VERSION ""

NS_ :

BS_:

BU_: XXX

BO_ 85 CID_MCWFAP: 8 XXX
 SG_ sig_uioige : 40|1@1+ (1,0) [0|1] "" XXX
 SG_ sig_wxbhky : 56|8@1+ (1,0) [0|255] "" XXX

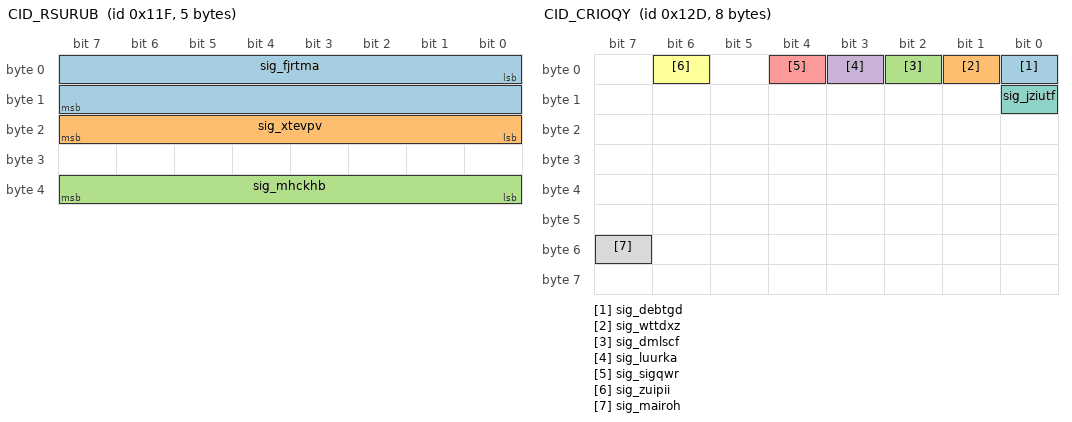
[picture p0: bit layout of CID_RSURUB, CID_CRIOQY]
BO_ 287 CID_RSURUB: 5 XXX
 SG_ sig_fjrtma : 0|16@1- (0.1,0) [-450|450] "" XXX
 SG_ sig_xtevpv : 16|8@1+ (4,0) [0|1020] "" XXX
 SG_ sig_mhckhb : 32|8@1+ (1,0) [0|255] "" XXX

BO_ 289 CID_NVMJEF: 8 XXX
 SG_ sig_wjivje : 0|12@1+ (1,0) [0|255] "" XXX

BO_ 301 CID_CRIOQY: 8 XXX
 SG_ sig_debtgd : 0|1@0+ (1,0) [0|1] "" XXX
 SG_ sig_wttdxz : 1|1@0+ (1,0) [0|1] "" XXX
 SG_ sig_dmlscf : 2|1@0+ (1,0) [0|1] "" XXX
 SG_ sig_luurka : 3|1@0+ (1,0) [0|1] "" XXX
 SG_ sig_sigqwr : 4|1@0+ (1,0) [0|1] "" XXX
 SG_ sig_zuipii : 6|1@0+ (1,0) [0|1] "" XXX
 SG_ sig_jziutf : 8|1@0+ (1,0) [0|1] "" XXX
 SG_ sig_mairoh : 55|1@0+ (1,0) [0|1] "" XXX

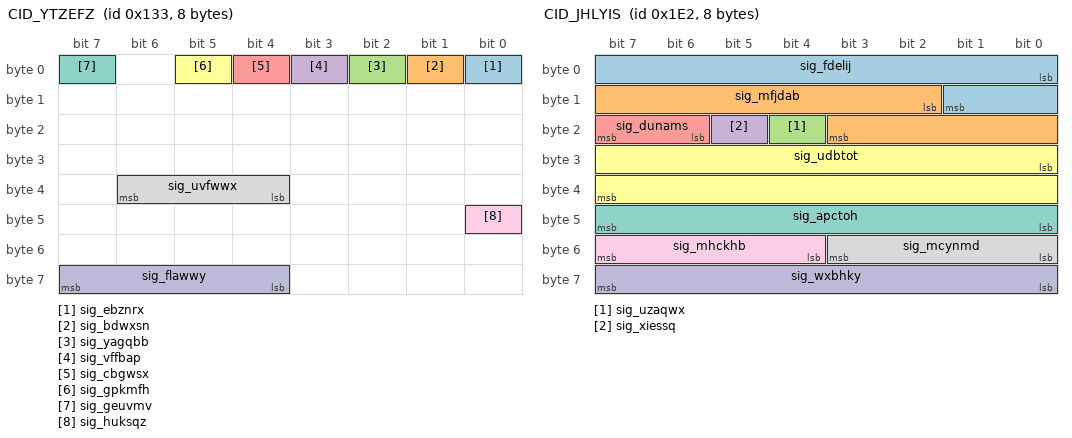
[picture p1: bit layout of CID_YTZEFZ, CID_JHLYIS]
BO_ 307 CID_YTZEFZ: 8 XXX
 SG_ sig_ebznrx : 0|1@0+ (1,0) [0|1] "" XXX
 SG_ sig_bdwxsn : 1|1@1+ (1,0) [0|1] "" XXX
 SG_ sig_yagqbb : 2|1@1+ (1,0) [0|1] "" XXX
 SG_ sig_vffbap : 3|1@1+ (1,0) [0|1] "" XXX
 SG_ sig_cbgwsx : 4|1@0+ (1,0) [0|1] "" XXX
 SG_ sig_gpkmfh : 5|1@0+ (1,0) [0|1] "" XXX
 SG_ sig_geuvmv : 7|1@0+ (1,0) [0|1] "" XXX
 SG_ sig_uvfwwx : 36|3@1+ (1,0) [0|7] "" XXX
 SG_ sig_huksqz : 40|1@0+ (1,0) [0|1] "" XXX
 SG_ sig_flawwy : 63|4@0+ (1,0) [0|15] "" XXX

BO_ 482 CID_JHLYIS: 8 XXX
 SG_ sig_fdelij : 0|10@1- (0.01,0) [0|5] "" XXX
 SG_ sig_mfjdab : 10|10@1- (0.01,0) [-5|0] "" XXX
 SG_ sig_uzaqwx : 20|1@0+ (1,0) [0|1] "" XXX
 SG_ sig_xiessq : 21|1@0+ (1,0) [0|1] "" XXX
 SG_ sig_dunams : 22|2@1+ (1,0) [0|1] "" XXX
 SG_ sig_udbtot : 24|16@1- (0.1,0) [-780|779.9] "" XXX
 SG_ sig_apctoh : 47|8@0+ (1,0) [0|255] "" XXX
 SG_ sig_mcynmd : 48|4@1+ (1,0) [0|15] "" XXX
 SG_ sig_mhckhb : 52|4@1+ (1,0) [0|15] "" XXX
 SG_ sig_wxbhky : 56|8@1+ (1,0) [0|255] "" XXX

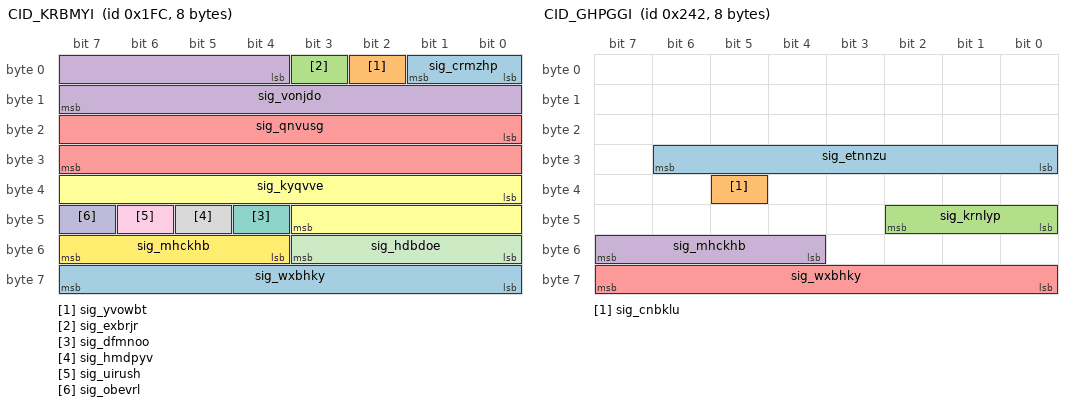
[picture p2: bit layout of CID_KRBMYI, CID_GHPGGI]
BO_ 508 CID_KRBMYI: 8 XXX
 SG_ sig_crmzhp : 0|2@1+ (1,0) [0|1] "" XXX
 SG_ sig_yvowbt : 2|1@1+ (1,0) [0|1] "" XXX
 SG_ sig_exbrjr : 3|1@0+ (1,0) [0|1] "" XXX
 SG_ sig_vonjdo : 4|12@1- (1,0) [-2048|2047] "" XXX
 SG_ sig_qnvusg : 16|16@1- (0.1,0) [-780|779.9] "Deg" XXX
 SG_ sig_kyqvve : 32|12@1- (0.01,0) [0|63] "" XXX
 SG_ sig_dfmnoo : 44|1@0+ (1,0) [0|1] "" XXX
 SG_ sig_hmdpyv : 45|1@1+ (1,0) [0|255] "" XXX
 SG_ sig_uirush : 46|1@1+ (1,0) [0|1] "" XXX
 SG_ sig_obevrl : 47|1@0+ (1,0) [0|3] "" XXX
 SG_ sig_hdbdoe : 48|4@1+ (1,0) [0|15] "" XXX
 SG_ sig_mhckhb : 52|4@1+ (1,0) [0|15] "" XXX
 SG_ sig_wxbhky : 56|8@1+ (1,0) [0|255] "" XXX

BO_ 578 CID_GHPGGI: 8 XXX
 SG_ sig_etnnzu : 30|7@0+ (1,0) [0|127] "" XXX
 SG_ sig_cnbklu : 37|1@0+ (1,0) [0|1] "" XXX
 SG_ sig_krnlyp : 40|3@1+ (1,0) [0|7] "" XXX
 SG_ sig_mhckhb : 55|4@0+ (1,0) [0|15] "" XXX
 SG_ sig_wxbhky : 56|8@1+ (1,0) [0|255] "" XXX

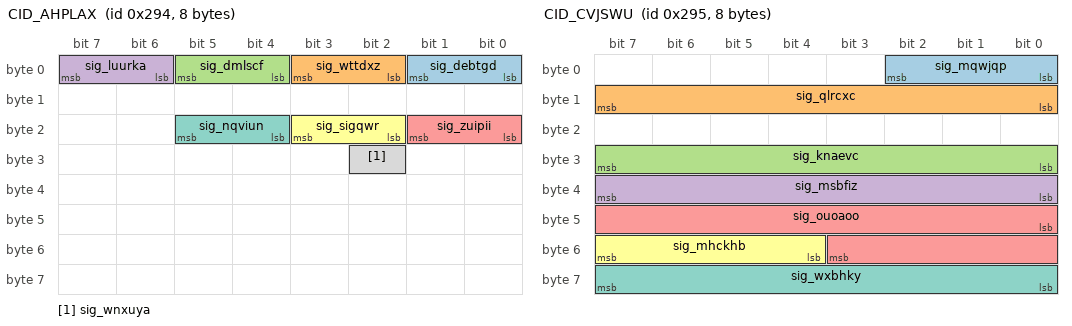
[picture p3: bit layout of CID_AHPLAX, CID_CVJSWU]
BO_ 660 CID_AHPLAX: 8 XXX
 SG_ sig_debtgd : 1|2@0+ (1,0) [0|3] "" XXX
 SG_ sig_wttdxz : 3|2@0+ (1,0) [0|3] "" XXX
 SG_ sig_dmlscf : 5|2@0+ (1,0) [0|3] "" XXX
 SG_ sig_luurka : 7|2@0+ (1,0) [0|3] "" XXX
 SG_ sig_zuipii : 17|2@0+ (1,0) [0|3] "" XXX
 SG_ sig_sigqwr : 19|2@0+ (1,0) [0|3] "" XXX
 SG_ sig_nqviun : 21|2@0+ (1,0) [0|3] "" XXX
 SG_ sig_wnxuya : 26|1@0+ (1,0) [0|1] "" XXX

BO_ 661 CID_CVJSWU: 8 XXX
 SG_ sig_mqwjqp : 2|3@0+ (1,0) [0|7] "" XXX
 SG_ sig_qlrcxc : 15|8@0+ (1,0) [0|255] "" XXX
 SG_ sig_knaevc : 31|8@0+ (1,0) [0|255] "" XXX
 SG_ sig_msbfiz : 32|8@1+ (1,0) [0|255] "" XXX
 SG_ sig_ouoaoo : 40|12@1+ (1,0) [0|255] "" XXX
 SG_ sig_mhckhb : 52|4@1+ (1,0) [0|15] "" XXX
 SG_ sig_wxbhky : 63|8@0+ (1,0) [0|255] "" XXX

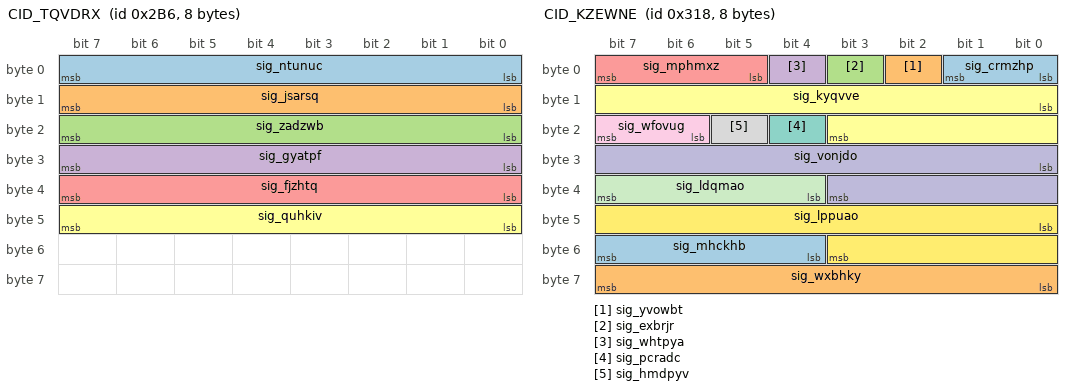
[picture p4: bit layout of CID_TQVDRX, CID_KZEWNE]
BO_ 694 CID_TQVDRX: 8 XXX
 SG_ sig_ntunuc : 7|8@0+ (1,0) [0|255] "" XXX
 SG_ sig_jsarsq : 15|8@0+ (1,0) [0|255] "" XXX
 SG_ sig_zadzwb : 23|8@0+ (1,0) [0|255] "" XXX
 SG_ sig_gyatpf : 31|8@0+ (1,0) [0|255] "" XXX
 SG_ sig_fjzhtq : 39|8@0+ (1,0) [0|255] "" XXX
 SG_ sig_quhkiv : 47|8@0+ (1,0) [0|255] "" XXX

BO_ 790 CID_GXPQAT: 8 XXX
 SG_ sig_eruibt : 3|4@0+ (1,0) [0|1] "" XXX
 SG_ sig_wxtitr : 4|2@1+ (1,0) [0|3] "" XXX
 SG_ sig_ldgngq : 6|2@1+ (1,0) [0|3] "" XXX
 SG_ sig_dbmyfr : 8|2@1+ (1,0) [0|3] "" XXX
 SG_ sig_kfomuy : 10|1@1+ (1,0) [0|1] "" XXX
 SG_ sig_quxrcd : 11|4@1+ (1,0) [0|1] "" XXX
 SG_ sig_xzjvxd : 15|1@0+ (1,0) [0|1] "" XXX
 SG_ sig_udbtot : 16|11@1- (1,0) [-1024|1023] "" XXX
 SG_ sig_uzaqwx : 27|1@1+ (1,0) [0|1] "" XXX
 SG_ sig_xiessq : 28|1@1+ (1,0) [0|3] "" XXX
 SG_ sig_ajmccf : 29|1@0+ (1,0) [0|1] "" XXX
 SG_ sig_bmieza : 30|1@0+ (1,0) [0|1] "" XXX
 SG_ sig_iwgpdw : 31|1@0+ (1,0) [0|1] "" XXX
 SG_ sig_npchrh : 32|2@1+ (1,0) [0|3] "" XXX
 SG_ sig_fcuins : 34|2@1+ (1,0) [0|3] "" XXX
 SG_ sig_bokbfa : 36|4@1+ (1,0) [0|3] "" XXX
 SG_ sig_xgamab : 40|8@1+ (5,-5) [-5|1270] "" XXX
 SG_ sig_jpladc : 49|2@0+ (1,0) [0|3] "" XXX
 SG_ sig_pifmxh : 51|2@0+ (1,0) [0|3] "" XXX
 SG_ sig_mhckhb : 52|4@1+ (1,0) [0|15] "" XXX
 SG_ sig_wxbhky : 56|8@1+ (1,0) [0|15] "" XXX

BO_ 792 CID_KZEWNE: 8 XXX
 SG_ sig_crmzhp : 0|2@1+ (1,0) [0|1] "" XXX
 SG_ sig_yvowbt : 2|1@1+ (1,0) [0|1] "" XXX
 SG_ sig_exbrjr : 3|1@1+ (1,0) [0|1] "" XXX
 SG_ sig_whtpya : 4|1@1+ (1,0) [0|1] "" XXX
 SG_ sig_mphmxz : 5|3@1+ (1,0) [0|1] "" XXX
 SG_ sig_kyqvve : 8|12@1- (1,0) [-2048|2047] "" XXX
 SG_ sig_pcradc : 20|1@1+ (1,0) [0|1] "" XXX
 SG_ sig_hmdpyv : 21|1@1+ (1,0) [0|1] "" XXX
 SG_ sig_wfovug : 22|2@1+ (1,0) [0|15] "" XXX
 SG_ sig_vonjdo : 24|12@1- (1,0) [-2048|2047] "" XXX
 SG_ sig_ldqmao : 36|4@1+ (1,0) [0|15] "" XXX
 SG_ sig_lppuao : 40|12@1+ (1,0) [0|4095] "" XXX
 SG_ sig_mhckhb : 52|4@1+ (1,0) [0|15] "" XXX
 SG_ sig_wxbhky : 56|8@1+ (1,0) [0|255] "" XXX

BO_ 813 CID_YPLUTP: 8 XXX
 SG_ sig_vwattl : 0|9@1+ (0.5,0) [0|255.5] "" XXX
 SG_ sig_aduxzo : 9|1@1+ (1,0) [0|1] "" XXX
 SG_ sig_vftgch : 10|3@1+ (1,0) [0|7] "" XXX
 SG_ sig_vqlcld : 13|3@1+ (1,0) [0|7] "" XXX
 SG_ sig_mdggcb : 16|1@1+ (1,0) [0|1] "" XXX
 SG_ sig_mbklmy : 17|1@1+ (1,0) [0|1] "" XXX
 SG_ sig_exbrjr : 18|1@1+ (1,0) [0|1] "" XXX
 SG_ sig_wngyio : 19|3@1+ (1,0) [0|1] "" XXX
 SG_ sig_pvngdg : 22|1@0+ (1,0) [0|1] "" XXX
 SG_ sig_luquuv : 23|1@0+ (1,0) [0|1] "" XXX
 SG_ sig_dbmyfr : 24|1@1+ (1,0) [0|1] "" XXX
 SG_ sig_blidrr : 25|7@1+ (1,0) [0|127] "" XXX
 SG_ sig_skcftn : 32|4@1+ (1,0) [0|15] "" XXX
 SG_ sig_temxkw : 36|12@1+ (1,0) [0|4095] "" XXX
 SG_ sig_mhckhb : 48|4@1+ (1,0) [0|15] "" XXX
 SG_ sig_rupdao : 55|4@0+ (1,0) [0|15] "" XXX
 SG_ sig_wxbhky : 56|8@1+ (1,0) [0|255] "" XXX

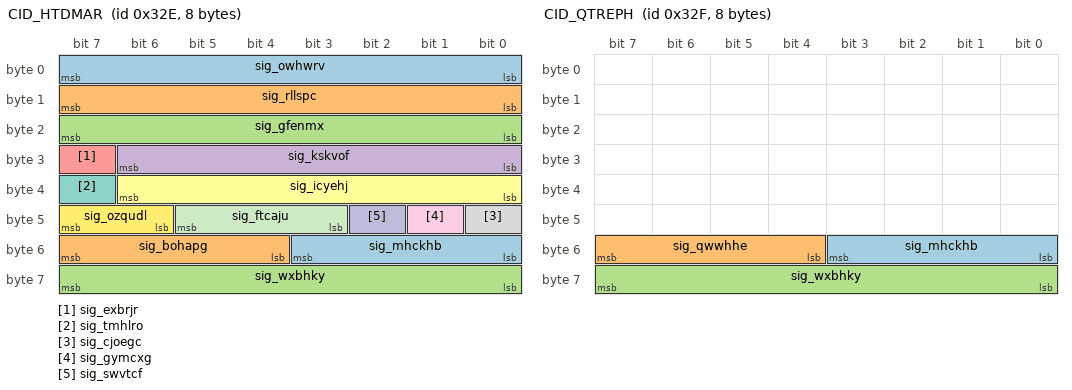
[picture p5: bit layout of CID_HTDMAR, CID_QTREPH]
BO_ 814 CID_HTDMAR: 8 XXX
 SG_ sig_owhwrv : 0|8@1+ (0.05,-5) [-100|155] "" XXX
 SG_ sig_rllspc : 8|8@1+ (0.05,-5) [0|1.26] "" XXX
 SG_ sig_gfenmx : 16|8@1+ (0.05,-5) [0|1.26] "" XXX
 SG_ sig_kskvof : 24|7@1+ (0.2,0) [0|12.7] "" XXX
 SG_ sig_exbrjr : 31|1@0+ (1,0) [0|1] "" XXX
 SG_ sig_icyehj : 32|7@1+ (0.2,-16) [0|12.7] "" XXX
 SG_ sig_tmhlro : 39|1@0+ (1,0) [0|1] "" XXX
 SG_ sig_cjoegc : 40|1@0+ (1,0) [0|1] "" XXX
 SG_ sig_gymcxg : 41|1@0+ (1,0) [0|1] "" XXX
 SG_ sig_swvtcf : 42|1@1+ (1,0) [0|3] "" XXX
 SG_ sig_ftcaju : 45|3@0+ (1,0) [0|1] "" XXX
 SG_ sig_ozqudl : 46|2@1+ (1,0) [0|3] "" XXX
 SG_ sig_mhckhb : 48|4@1+ (1,0) [0|15] "" XXX
 SG_ sig_bohapg : 55|4@0+ (1,0) [0|15] "" XXX
 SG_ sig_wxbhky : 56|8@1+ (1,0) [0|255] "" XXX

BO_ 815 CID_QTREPH: 8 XXX
 SG_ sig_mhckhb : 48|4@1+ (1,0) [0|15] "" XXX
 SG_ sig_qwwhhe : 55|4@0+ (1,0) [0|15] "" XXX
 SG_ sig_wxbhky : 56|8@1+ (1,0) [0|255] "" XXX

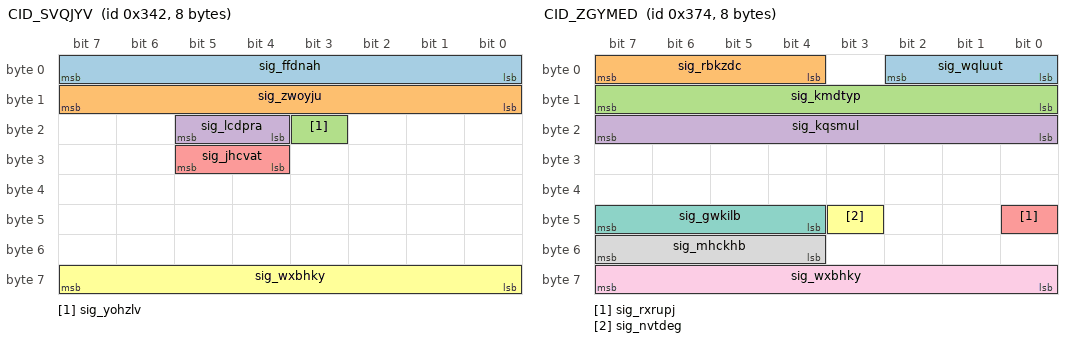
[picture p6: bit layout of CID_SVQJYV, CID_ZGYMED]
BO_ 834 CID_SVQJYV: 8 XXX
 SG_ sig_ffdnah : 0|8@1+ (0.01,0) [0|2.55] "" XXX
 SG_ sig_zwoyju : 8|8@1+ (0.01,0) [0|2.55] "" XXX
 SG_ sig_yohzlv : 19|1@1+ (1,0) [0|1] "" XXX
 SG_ sig_lcdpra : 20|2@1+ (1,0) [0|255] "" XXX
 SG_ sig_jhcvat : 28|2@1+ (1,0) [0|1] "" XXX
 SG_ sig_wxbhky : 56|8@1+ (1,0) [0|255] "" XXX

 BO_ 884 CID_ZGYMED: 8 MRR
 SG_ sig_wqluut : 2|3@0+ (1,0) [0|3] "" MRR
 SG_ sig_rbkzdc : 7|4@0+ (1,0) [0|15] "" MRR
 SG_ sig_kmdtyp : 15|8@0+ (0.1,-12) [0|255] "" MRR
 SG_ sig_kqsmul : 23|8@0+ (1,-100) [0|255] "" MRR
 SG_ sig_rxrupj : 40|1@0+ (1,0) [0|3] "" MRR
 SG_ sig_nvtdeg : 43|1@0+ (1,0) [0|1] "" XXX
 SG_ sig_gwkilb : 44|4@1+ (1,0) [0|15] "" XXX
 SG_ sig_mhckhb : 52|4@1+ (1,0) [0|15] "" MRR
 SG_ sig_wxbhky : 56|8@1+ (1,0) [0|255] "" MRR

BO_ 944 CID_WLXZOF: 8 XXX
 SG_ sig_ezdbxm : 1|2@0+ (1,0) [0|3] "" XXX
 SG_ sig_itykpr : 2|1@0+ (1,0) [0|1] "" XXX
 SG_ sig_tksxga : 4|2@0+ (1,0) [0|3] "" XXX
 SG_ sig_dqfgmo : 5|1@0+ (1,0) [0|1] "" XXX
 SG_ sig_qjgeiy : 6|1@0+ (1,0) [0|1] "" XXX
 SG_ sig_gwhdhq : 7|1@0+ (1,0) [0|1] "" XXX
 SG_ sig_giraji : 8|1@0+ (1,0) [0|1] "" XXX
 SG_ sig_xcvbhu : 11|3@0+ (1,0) [0|7] "" XXX
 SG_ sig_dgobck : 12|1@0+ (1,0) [0|1] "" XXX
 SG_ sig_dgolgp : 14|2@0+ (1,0) [0|3] "" XXX
 SG_ sig_oqgwux : 15|1@0+ (1,0) [0|1] "" XXX
 SG_ sig_qxvnqs : 16|1@0+ (1,0) [0|1] "" XXX
 SG_ sig_frmyep : 18|2@0+ (1,0) [0|3] "" XXX
 SG_ sig_lvjnec : 19|1@0+ (1,0) [0|1] "" XXX
 SG_ sig_kwfcwc : 23|4@0+ (1,0) [0|15] "" XXX
 SG_ sig_moejql : 24|28@1+ (1,0) [0|268435455] "" XXX
 SG_ sig_mhckhb : 52|4@1+ (1,0) [0|15] "" XXX
 SG_ sig_wxbhky : 56|8@1+ (1,0) [0|255] "" XXX

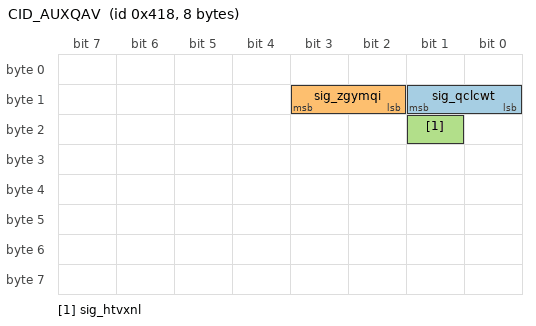
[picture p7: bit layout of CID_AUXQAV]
BO_ 1048 CID_AUXQAV: 8 XXX
 SG_ sig_qclcwt : 9|2@0+ (1,0) [0|1] "" XXX
 SG_ sig_zgymqi : 11|2@0+ (1,0) [0|1] "" XXX
 SG_ sig_htvxnl : 17|1@0+ (1,0) [0|1] "" XXX

VAL_ 578 sig_krnlyp 4 "D" 2 "R" 3 "N" 1 "P";
VAL_ 790 sig_eruibt 11 "AutoFullBeamActive" 2 "AutoFullBeamInactive";
VAL_ 790 sig_wxtitr 0 "GRAY" 1 "GREEN" 2 "YELLOW" 3 "RED";
VAL_ 790 sig_ldgngq 3 "ALARM_AND_LKA" 2 "LKA" 1 "ALARM" 0 "DISABLE";
VAL_ 790 sig_fcuins 0 "GRAY" 1 "GREEN" 2 "YELLOW" 3 "RED";
VAL_ 790 sig_jpladc 0 "VIBRATION" 1 "AUDIO" 2 "AUDIO_AND_VIBRATION";
VAL_ 792 sig_crmzhp 0 "NotReady" 1 "Ready" 2 "Active" 3 "TemporaryFail";
VAL_ 813 sig_vftgch 4 "4BAR" 3 "3BAR" 2 "2BAR" 1 "1BAR";
VAL_ 813 sig_wngyio 0 "OFF" 2 "ACC_ON" 3 "ACC_ACTIVE" 5 "FORCE_ACCEL" 7 "ERROR";
VAL_ 813 sig_blidrr 36 "ACC_ERROR" 22 "OVERRIDE" 12 "ENGAGE" 8 "DISENGAGE" 20 "ACC_ON" 32 "ACC_OFF" 48 "CHECK_GEAR_D" 16 "FORCE_ACCEL" 0 "NONE";
VAL_ 814 sig_ftcaju 0 "Off" 1 "Passive" 2 "StandBy" 3 "ActiveControl" 4 "BrakeOnly" 5 "Override" 6 "Standstill" 7 "Failure";
VAL_ 814 sig_ozqudl 0 "Softoff" 1 "Fastoff" 2 "Immediateoff" 3 "Initial";
VAL_ 834 sig_lcdpra 2 "SPORT" 1 "ECO" 0 "SNOW";
VAL_ 834 sig_jhcvat 3 "HEV" 2 "FORCE_EV" 1 "EV";
VAL_ 944 sig_tksxga 0 "NOTPRESSED" 1 "DOWN_SETSPEED" 3 "UP_RESETSPEED";
